# ESP32C5_RADIO register map
Vendor: Espressif; Series: ESP32-C5; File version: 0.1
Registers are 32-bit, read-write, no defined reset value unless marked. A register's access mark holds for its fields unless they carry their own. Offsets are from the block's base; [hi:lo] are bit positions; lines under a group give offsets from that group; {n}, {i} and the like mark numbered series.

## TIMG0_WDT — Timer group 0's main watchdog (MWDT0): only its configuration, feed and write-protect words; the timers and the RTC calibration words of the group are not part of this view.
Base 0x60008000
Same registers: TIMG1_WDT 0x60009000
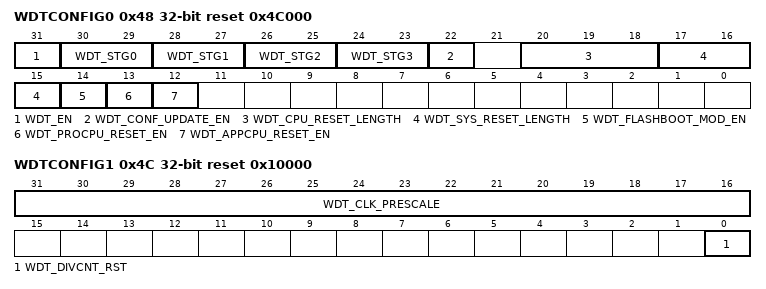
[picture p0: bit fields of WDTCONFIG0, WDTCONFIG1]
0x48 WDTCONFIG0 reset 0x4C000 — Main watchdog enable, stage actions, reset lengths and the configuration latch; written only while unlocked.
  [31] WDT_EN — Main watchdog enable.
  [30-2n:29-2n] WDT_STG{n} (n=0..3) — Timeout action of stage {n}: 0 none, 1 interrupt, 2 CPU reset, 3 system reset.
  [22] WDT_CONF_UPDATE_EN wo — Writing one latches the watchdog configuration words into the watchdog clock domain; reads zero.
  [20:18] WDT_CPU_RESET_LENGTH — CPU reset signal length: 0..7 select 8, 16, 24, 32, 40, 64, 128 or 256 watchdog clock cycles.
  [17:15] WDT_SYS_RESET_LENGTH — System reset signal length: 0..7 select 8, 16, 24, 32, 40, 64, 128 or 256 watchdog clock cycles.
  [14] WDT_FLASHBOOT_MOD_EN — Flash boot protection: the ROM arms it; a timeout resets the system even while WDT_EN is clear.
  [13] WDT_PROCPU_RESET_EN — Unmasks the CPU reset of the protocol core.
  [12] WDT_APPCPU_RESET_EN — Unmasks the CPU reset of the application core.
0x4C WDTCONFIG1 reset 0x10000 — Main watchdog clock prescaler and divider reset; written only while unlocked.
  [31:16] WDT_CLK_PRESCALE — Watchdog tick = source clock period times this prescaler.
  [0] WDT_DIVCNT_RST wo — Writing one resets the prescaler's divider counter; reads zero.
0x50 WDTCONFIG2 reset 0x18CBA80 — Stage 0 timeout; written only while unlocked.
  [31:0] WDT_STG0_HOLD — Stage 0 timeout in watchdog ticks.
0x60 WDTFEED wo reset 0x0 — Writing any value feeds the main watchdog while unlocked.
  [31:0] WDT_FEED — Any written value restarts the watchdog from stage 0.
0x64 WDTWPROTECT reset 0x50D83AA1 — Main watchdog write protection: the key unlocks the watchdog words, any other value locks them.
  [31:0] WDT_WKEY — Write key; 0x50D83AA1 unlocks.

## LP_WDT — The RTC watchdog (RWDT) of the low-power watchdog block: its configuration word and write protection. The super watchdog's words are the separate LP_WDT_SWD view.
Base 0x600B1C00
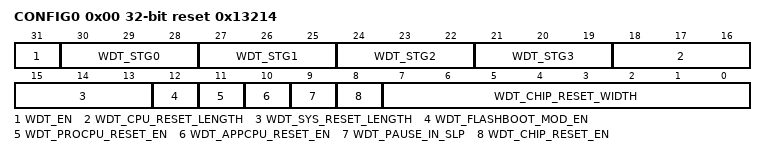
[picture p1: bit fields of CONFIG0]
0x00 CONFIG0 reset 0x13214 — RTC watchdog enable, stage actions and reset lengths; written only while unlocked.
  [31] WDT_EN — RTC watchdog enable.
  [30-3n:28-3n] WDT_STG{n} (n=0..3) — Timeout action of stage {n}: 0 none, 1 interrupt, 2 CPU reset, 3 system reset, 4 RTC reset.
  [18:16] WDT_CPU_RESET_LENGTH — CPU reset signal length selector.
  [15:13] WDT_SYS_RESET_LENGTH — System reset signal length selector.
  [12] WDT_FLASHBOOT_MOD_EN — Flash boot protection: the ROM arms it; a timeout resets even while WDT_EN is clear.
  [11] WDT_PROCPU_RESET_EN — Unmasks the CPU reset of the protocol core.
  [10] WDT_APPCPU_RESET_EN — Unmasks the CPU reset of the application core.
  [9] WDT_PAUSE_IN_SLP — Pauses the watchdog while the chip sleeps.
  [8] WDT_CHIP_RESET_EN — Enables the chip reset on timeout.
  [7:0] WDT_CHIP_RESET_WIDTH — Chip reset signal width.
0x18 WPROTECT reset 0x0 — RTC watchdog write protection: the key unlocks CONFIG0 to FEED, any other value locks them.
  [31:0] WDT_WKEY — Write key; 0x50D83AA1 unlocks.

## LP_WDT_SWD — The super watchdog (SWD) of the low-power watchdog block: its configuration word and write protection.
Base 0x600B1C00
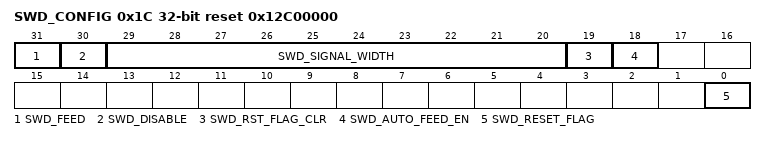
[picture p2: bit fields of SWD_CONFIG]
0x1C SWD_CONFIG reset 0x12C00000 — Super watchdog control; written only while unlocked.
  [31] SWD_FEED wo — Writing one feeds the super watchdog; reads zero.
  [30] SWD_DISABLE — Disables the super watchdog.
  [29:20] SWD_SIGNAL_WIDTH — Width of the super watchdog's reset signal.
  [19] SWD_RST_FLAG_CLR wo — Writing one clears SWD_RESET_FLAG; reads zero.
  [18] SWD_AUTO_FEED_EN — The hardware feeds the super watchdog by itself.
  [0] SWD_RESET_FLAG ro — Set when the super watchdog reset the chip.
0x20 SWD_WPROTECT reset 0x0 — Super watchdog write protection: the key unlocks SWD_CONFIG, any other value locks it.
  [31:0] SWD_WKEY — Write key; 0x50D83AA1 unlocks.
